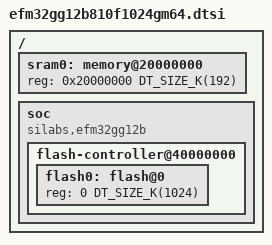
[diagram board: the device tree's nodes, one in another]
/*
 * Copyright (c) 2023 Antmicro <www.antmicro.com>
 *
 * SPDX-License-Identifier: Apache-2.0
 */

#include <mem.h>
#include <silabs/efm32gg12b.dtsi>

/ {
	sram0: memory@20000000 {
		reg = <0x20000000 DT_SIZE_K(192)>;
	};

	soc {
		compatible = "silabs,efm32gg12b", "silabs,efm32gg12",
			"silabs,efm32", "simple-bus";

		flash-controller@40000000 {
			flash0: flash@0 {
				reg = <0 DT_SIZE_K(1024)>;
			};
		};
	};

};
